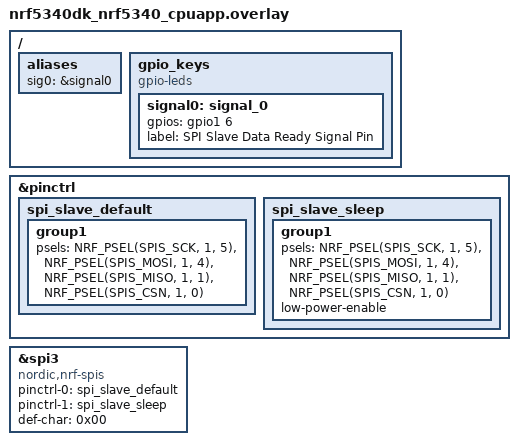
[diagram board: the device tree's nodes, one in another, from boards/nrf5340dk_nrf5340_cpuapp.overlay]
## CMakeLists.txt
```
#-------------------------------------------------------------------------------
# Zephyr Example Application
#
# Copyright (c) 2021 Nordic Semiconductor ASA
# SPDX-License-Identifier: Apache-2.0

cmake_minimum_required(VERSION 3.20.0)
find_package(Zephyr REQUIRED HINTS $ENV{ZEPHYR_BASE})

project(app LANGUAGES C)

target_sources(app PRIVATE src/main.c)





#-------------------------------------------------------------------------------
# Zephyr Example Application
#
# Copyright (c) 2021 Nordic Semiconductor ASA
# SPDX-License-Identifier: Apache-2.0

# cmake_minimum_required(VERSION 3.20.0)

# find_package(Zephyr REQUIRED HINTS $ENV{ZEPHYR_BASE})

# project(gateway_lower LANGUAGES C)

# # Note that here, we're adding CMAKE_SOURCE_DIR to the include path for nanopb.
# # This is needed because the below call to nanopb_generate_cpp() is using
# # 'RELPATH .'
# set(NANOPB_OPTIONS "-I${CMAKE_SOURCE_DIR}")
# nanopb_generate_cpp(proto_sources proto_headers RELPATH .
#     protobuf/time.proto
# )
# # we need to be able to include generated header files
# zephyr_library_include_directories(${CMAKE_CURRENT_BINARY_DIR})

# target_sources(app PRIVATE ${proto_sources})


# # Include files that are common for all modules
# add_subdirectory(src/common/dev_id)
# add_subdirectory(src/common/message_channel)

# # add_subdirectory_ifdef(CONFIG_UPLINK src/modules/uplink)

# # Include mandatory module source folders
# add_subdirectory(src/modules/core)
# add_subdirectory(src/modules/uplink)
# add_subdirectory(src/modules/downlink) # convert to optional later (see below)
# add_subdirectory(src/modules/systime)
# add_subdirectory(src/modules/error)

# Optional modules
# add_subdirectory_ifdef(CONFIG_NOT_EDGE_DEVICE src/modules/dnlink)
```

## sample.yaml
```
# This file is provided so that the application can be compiled using Twister,
# the Zephyr testing tool. In this file, multiple combinations can be specified,
# so that you can easily test all of them locally or in CI.
sample:
  description: Example application
  name: gateway-lower
common:
  build_only: true
  integration_platforms:
    - custom_plank
    - nucleo_f302r8
tests:
  app.default: {}
  app.debug:
    extra_overlay_confs:
      - debug.conf
```

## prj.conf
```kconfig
# Copyright (c) 2021 Nordic Semiconductor ASA
# SPDX-License-Identifier: Apache-2.0
#
# This file contains selected Kconfig options for the application.

CONFIG_LOG=y
CONFIG_LOG_MODE_IMMEDIATE=y
# CONFIG_LOG_MODE_DEFERRED=y
CONFIG_ASSERT=y
CONFIG_THREAD_NAME=y
CONFIG_INIT_STACKS=y
CONFIG_STACK_SENTINEL=y
# CONFIG_SHELL=y

CONFIG_SPI=y
CONFIG_SPI_ASYNC=y
CONFIG_SPI_SLAVE=y
# CONFIG_SPI_LOG_LEVEL_DBG=y

# ZBUS
CONFIG_ZBUS=y
CONFIG_ZBUS_LOG_LEVEL_INF=y
CONFIG_ZBUS_CHANNEL_NAME=y
CONFIG_ZBUS_OBSERVER_NAME=y

# General
# CONFIG_HW_ID_LIBRARY=y
CONFIG_HWINFO=y
CONFIG_REBOOT=y
CONFIG_FPU=y
CONFIG_HEAP_MEM_POOL_SIZE=40960

# Nanopb
CONFIG_NANOPB=y

# Date Time library
CONFIG_POSIX_CLOCK=y
CONFIG_NEWLIB_LIBC=y
# # CONFIG_NEWLIB_LIBC_FLOAT_PRINTF=y
# CONFIG_DATE_TIME=y
# CONFIG_DATE_TIME_NTP=n
# CONFIG_DATE_TIME_UPDATE_INTERVAL_SECONDS=0
# CONFIG_DATE_TIME_TOO_OLD_SECONDS=0

# CONFIG_ZIOTA=y
# CONFIG_UPLINK=y
# CONFIG_UPLINK_MOCK=y
```

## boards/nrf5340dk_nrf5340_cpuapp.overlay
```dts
/ {
	aliases {
		sig0 = &signal0;
	};

	gpio_keys {
		compatible = "gpio-leds";
		signal0: signal_0 {
			gpios = <&gpio1 6 GPIO_ACTIVE_HIGH>;
			label = "SPI Slave Data Ready Signal Pin";
		};
	};
};

&pinctrl {
	spi_slave_default: spi_slave_default {
		group1 {
			psels = <NRF_PSEL(SPIS_SCK, 1, 5)>,
					<NRF_PSEL(SPIS_MOSI, 1, 4)>,
					<NRF_PSEL(SPIS_MISO, 1, 1)>,
					<NRF_PSEL(SPIS_CSN, 1, 0)>;
		};
	};

	spi_slave_sleep: spi_slave_sleep {
		group1 {
			psels = <NRF_PSEL(SPIS_SCK, 1, 5)>,
					<NRF_PSEL(SPIS_MOSI, 1, 4)>,
					<NRF_PSEL(SPIS_MISO, 1, 1)>,
					<NRF_PSEL(SPIS_CSN, 1, 0)>;
			low-power-enable;
		};
	};
};

my_spi_slave: &spi3 {
	compatible = "nordic,nrf-spis";
	status = "okay";
	pinctrl-0 = <&spi_slave_default>;
	pinctrl-1 = <&spi_slave_sleep>;
	pinctrl-names = "default", "sleep";
	def-char = <0x00>;
};

// PIN | ESP32S2 -> NRF5340
// CSEL| 34         1.0
// MISO| 37         1.1
// MOSI| 35         1.4
// SCLK| 36         1.5
```

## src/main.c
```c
/*
 * Copyright (c) 2012-2014 Wind River Systems, Inc.
 *
 * SPDX-License-Identifier: Apache-2.0
 */

#include <zephyr/kernel.h>

int main(void)
{
	printk("Hello World! %s\n", CONFIG_BOARD);
	return 0;
}
```
